# PL011 register map
File version: 1
PrimeCell UART register interface
Registers are read-write, no defined reset value unless marked. A register's access mark holds for its fields unless they carry their own. Offsets are from the block's base; lines under a group give offsets from that group; [hi:lo] are bit positions; {n}, {i} and the like mark numbered series; 'fields as' and 'values as' point back to an identical list; <NAME> marks a mode.

## Memory map
0x00000000 PL011 size 0x1000

## PL011
Base 0x00000000
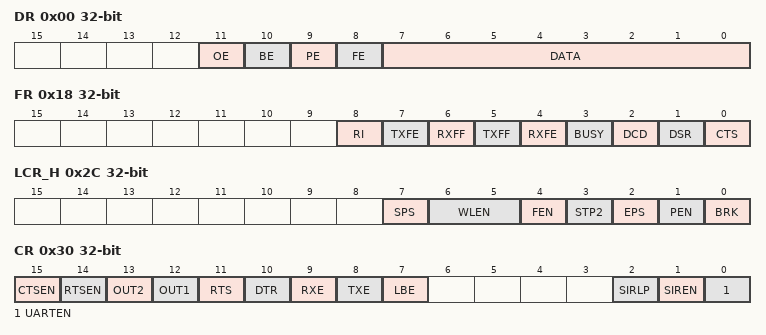
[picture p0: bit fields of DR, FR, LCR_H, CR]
0x00 DR read-modifies
  [11] OE ro, [10] BE ro, [9] PE ro, [8] FE ro, [7:0] DATA
0x18 FR ro
  [8] RI, [7] TXFE, [6] RXFF, [5] TXFF, [4] RXFE, [3] BUSY, [2] DCD, [1] DSR, [0] CTS
0x24 IBRD
  [15:0] DIVINT
0x28 FBRD
  [5:0] DIVFRAC
0x2C LCR_H
  [7] SPS, [6:5] WLEN, [4] FEN, [3] STP2, [2] EPS, [1] PEN, [0] BRK
0x30 CR
  [15] CTSEN, [14] RTSEN, [13] OUT2, [12] OUT1, [11] RTS, [10] DTR, [9] RXE, [8] TXE, [7] LBE, [2] SIRLP, [1] SIREN, [0] UARTEN
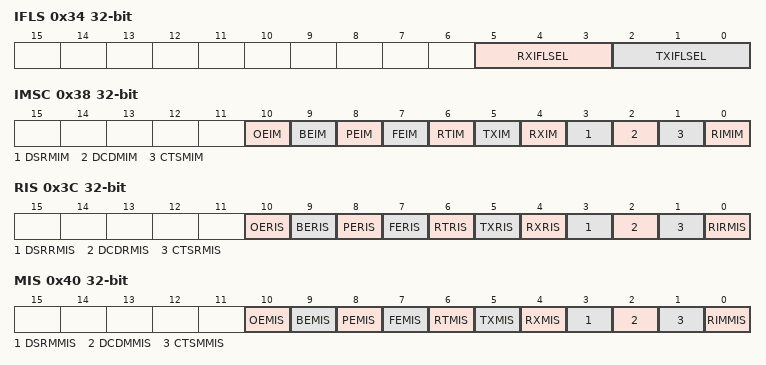
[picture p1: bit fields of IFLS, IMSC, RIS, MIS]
0x34 IFLS
  [5:3] RXIFLSEL, [2:0] TXIFLSEL
0x38 IMSC
  [10] OEIM, [9] BEIM, [8] PEIM, [7] FEIM, [6] RTIM, [5] TXIM, [4] RXIM, [3] DSRMIM, [2] DCDMIM, [1] CTSMIM, [0] RIMIM
0x3C RIS ro
  [10] OERIS, [9] BERIS, [8] PERIS, [7] FERIS, [6] RTRIS, [5] TXRIS, [4] RXRIS, [3] DSRRMIS, [2] DCDRMIS, [1] CTSRMIS, [0] RIRMIS
0x40 MIS ro
  [10] OEMIS, [9] BEMIS, [8] PEMIS, [7] FEMIS, [6] RTMIS, [5] TXMIS, [4] RXMIS, [3] DSRMMIS, [2] DCDMMIS, [1] CTSMMIS, [0] RIMMIS
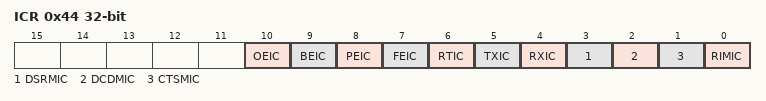
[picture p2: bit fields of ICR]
0x44 ICR wo
  [10] OEIC write-1-clears, [9] BEIC write-1-clears, [8] PEIC write-1-clears, [7] FEIC write-1-clears, [6] RTIC write-1-clears, [5] TXIC write-1-clears, [4] RXIC write-1-clears, [3] DSRMIC write-1-clears, [2] DCDMIC write-1-clears, [1] CTSMIC write-1-clears, [0] RIMIC write-1-clears

## Notices in the file
Copyright (c) 2026, Stanislav Sedov <stas@deglitch.com>
SPDX-License-Identifier: BSD-2-Clause
